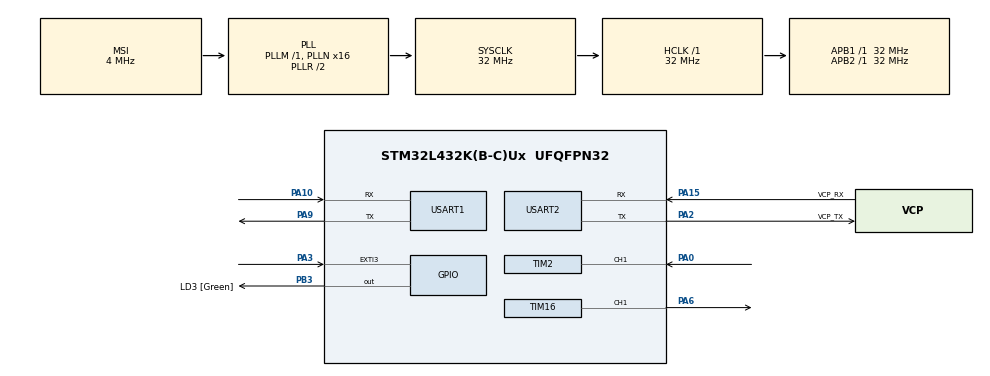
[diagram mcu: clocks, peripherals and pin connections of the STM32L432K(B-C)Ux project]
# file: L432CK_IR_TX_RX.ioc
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Dma.Request0=USART1_RX
Dma.Request1=USART1_TX
Dma.Request2=USART2_TX
Dma.USART1_RX.0.Direction=DMA_PERIPH_TO_MEMORY
Dma.USART1_RX.0.Instance=DMA1_Channel5
Dma.USART1_RX.0.MemDataAlignment=DMA_MDATAALIGN_BYTE
Dma.USART1_RX.0.MemInc=DMA_MINC_ENABLE
Dma.USART1_RX.0.Mode=DMA_CIRCULAR
Dma.USART1_RX.0.PeriphDataAlignment=DMA_PDATAALIGN_BYTE
Dma.USART1_RX.0.PeriphInc=DMA_PINC_DISABLE
Dma.USART1_RX.0.Priority=DMA_PRIORITY_MEDIUM
Dma.USART1_TX.1.Direction=DMA_MEMORY_TO_PERIPH
Dma.USART1_TX.1.Instance=DMA1_Channel4
Dma.USART1_TX.1.MemDataAlignment=DMA_MDATAALIGN_BYTE
Dma.USART1_TX.1.MemInc=DMA_MINC_ENABLE
Dma.USART1_TX.1.Mode=DMA_NORMAL
Dma.USART1_TX.1.PeriphDataAlignment=DMA_PDATAALIGN_BYTE
Dma.USART1_TX.1.PeriphInc=DMA_PINC_DISABLE
Dma.USART1_TX.1.Priority=DMA_PRIORITY_LOW
Dma.USART2_TX.2.Direction=DMA_MEMORY_TO_PERIPH
Dma.USART2_TX.2.Instance=DMA1_Channel7
Dma.USART2_TX.2.MemDataAlignment=DMA_MDATAALIGN_BYTE
Dma.USART2_TX.2.MemInc=DMA_MINC_ENABLE
Dma.USART2_TX.2.Mode=DMA_NORMAL
Dma.USART2_TX.2.PeriphDataAlignment=DMA_PDATAALIGN_BYTE
Dma.USART2_TX.2.PeriphInc=DMA_PINC_DISABLE
Dma.USART2_TX.2.Priority=DMA_PRIORITY_LOW
Mcu.Family=STM32L4
Mcu.Name=STM32L432K(B-C)Ux
Mcu.Package=UFQFPN32
NVIC.DMA1_Channel4_IRQn=true\:0\:0\:false\:false\:true\:false\:true\:true
NVIC.DMA1_Channel5_IRQn=true\:0\:0\:false\:false\:true\:false\:true\:true
NVIC.DMA1_Channel7_IRQn=true\:0\:0\:false\:false\:true\:false\:true\:true
NVIC.EXTI3_IRQn=true\:3\:0\:true\:false\:true\:true\:true\:true
NVIC.PriorityGroup=NVIC_PRIORITYGROUP_4
NVIC.TIM1_BRK_TIM15_IRQn=true\:2\:0\:true\:false\:true\:true\:true\:true
NVIC.TIM2_IRQn=true\:1\:0\:true\:false\:true\:true\:true\:true
NVIC.USART1_IRQn=true\:0\:0\:false\:false\:true\:true\:true\:true
NVIC.USART2_IRQn=true\:0\:0\:false\:false\:true\:true\:true\:true
PA0.Signal=S_TIM2_CH1
PA10.Mode=Asynchronous
PA10.Signal=USART1_RX
PA13\ (JTMS-SWDIO).GPIO_Label=SWDIO
PA13\ (JTMS-SWDIO).Mode=Serial_Wire
PA13\ (JTMS-SWDIO).Signal=SYS_JTMS-SWDIO
PA14\ (JTCK-SWCLK).GPIO_Label=SWCLK
PA14\ (JTCK-SWCLK).Mode=Serial_Wire
PA14\ (JTCK-SWCLK).Signal=SYS_JTCK-SWCLK
PA15\ (JTDI).GPIO_Label=VCP_RX
PA15\ (JTDI).Mode=Asynchronous
PA15\ (JTDI).Signal=USART2_RX
PA2.GPIO_Label=VCP_TX
PA2.Mode=Asynchronous
PA2.Signal=USART2_TX
PA3.Signal=GPXTI3
PA6.Signal=S_TIM16_CH1
PA9.Mode=Asynchronous
PA9.Signal=USART1_TX
PB3\ (JTDO-TRACESWO).GPIO_Label=LD3 [Green]
PB3\ (JTDO-TRACESWO).Signal=GPIO_Output
ProjectManager.HeapSize=0x200
ProjectManager.StackSize=0x400
ProjectManager.TargetToolchain=MDK-ARM V5.32
RCC.AHBFreq_Value=32000000
RCC.APB1Freq_Value=32000000
RCC.APB1TimFreq_Value=32000000
RCC.APB2Freq_Value=32000000
RCC.APB2TimFreq_Value=32000000
RCC.CortexFreq_Value=32000000
RCC.HCLKFreq_Value=32000000
RCC.HSE_VALUE=8000000
RCC.HSI16_VALUE=16000000
RCC.HSI48_VALUE=48000000
RCC.HSI_VALUE=16000000
RCC.LSE_VALUE=32768
RCC.MSI_VALUE=4000000
RCC.PLLMUL=RCC_PLLMUL_4
RCC.PLLN=16
RCC.SYSCLKFreq_VALUE=32000000
RCC.SYSCLKSource=RCC_SYSCLKSOURCE_PLLCLK
RCC.VCOOutputFreq_Value=64000000
SH.S_TIM16_CH1.0=TIM16_CH1,PWM Generation1 CH1
SH.S_TIM2_CH1.0=TIM2_CH1,PWM_Input_1
TIM15.AutoReloadPreload=TIM_AUTORELOAD_PRELOAD_ENABLE
TIM15.Period=888
TIM15.Prescaler=31
TIM15.TIM_MasterOutputTrigger=TIM_TRGO_RESET
TIM16.AutoReloadPreload=TIM_AUTORELOAD_PRELOAD_ENABLE
TIM16.Channel=TIM_CHANNEL_1
TIM16.Period=842
TIM16.Pulse=210
TIM2.ICPolarity_1=TIM_INPUTCHANNELPOLARITY_FALLING
TIM2.Period=3700
TIM2.Prescaler=31
TIM2.TIM_MasterOutputTrigger=TIM_TRGO_RESET
USART1.VirtualMode-Asynchronous=VM_ASYNC
USART2.VirtualMode-Asynchronous=VM_ASYNC
VP_TIM15_VS_ClockSourceINT.Mode=Internal
VP_TIM16_VS_ClockSourceINT.Mode=Enable_Timer
VP_TIM2_VS_ClockSourceINT.Mode=Internal
board=NUCLEO-L432KC

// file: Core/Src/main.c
/* USER CODE BEGIN Header */
/**
  ******************************************************************************
  * @file           : main.c
  * @brief          : Main program body
  ******************************************************************************
  * @attention
  *
  * Copyright (c) 2026 STMicroelectronics.
  * All rights reserved.
  *
  * This software is licensed under terms that can be found in the LICENSE file
  * in the root directory of this software component.
  * If no LICENSE file comes with this software, it is provided AS-IS.
  *
  ******************************************************************************
  */
/* USER CODE END Header */
#include "main.h"

/* USER CODE BEGIN Includes */
#include "app_ble_ir.h"
/* USER CODE END Includes */

TIM_HandleTypeDef htim2;
TIM_HandleTypeDef htim15;
TIM_HandleTypeDef htim16;

UART_HandleTypeDef huart1;
UART_HandleTypeDef huart2;
DMA_HandleTypeDef hdma_usart1_rx;
DMA_HandleTypeDef hdma_usart1_tx;
DMA_HandleTypeDef hdma_usart2_tx;

void SystemClock_Config(void);
static void MX_GPIO_Init(void);
static void MX_DMA_Init(void);
static void MX_USART2_UART_Init(void);
static void MX_TIM2_Init(void);
static void MX_TIM15_Init(void);
static void MX_TIM16_Init(void);
static void MX_USART1_UART_Init(void);

/* USER CODE BEGIN 0 */
void HAL_GPIO_EXTI_Callback(uint16_t GPIO_Pin)
{
  App_BleIr_OnExti(GPIO_Pin);
}
/* USER CODE END 0 */

int main(void)
{

  /* MCU Configuration--------------------------------------------------------*/

  /* Reset of all peripherals, Initializes the Flash interface and the Systick. */
  HAL_Init();

  /* Configure the system clock */
  SystemClock_Config();

  /* Initialize all configured peripherals */
  MX_GPIO_Init();
  MX_DMA_Init();
  MX_USART2_UART_Init();
  MX_TIM2_Init();
  MX_TIM15_Init();
  MX_TIM16_Init();
  MX_USART1_UART_Init();
  /* USER CODE BEGIN 2 */
  App_BleIr_Init();

  /* USER CODE END 2 */

  /* Infinite loop */
  while (1)
  {

    /* USER CODE BEGIN 3 */
    App_BleIr_Process();
  }
  /* USER CODE END 3 */
}

void SystemClock_Config(void)
{
  RCC_OscInitTypeDef RCC_OscInitStruct = {0};
  RCC_ClkInitTypeDef RCC_ClkInitStruct = {0};

  /** Configure the main internal regulator output voltage
  */
  if (HAL_PWREx_ControlVoltageScaling(PWR_REGULATOR_VOLTAGE_SCALE1) != HAL_OK)
  {
    Error_Handler();
  }

  /** Initializes the RCC Oscillators according to the specified parameters
  * in the RCC_OscInitTypeDef structure.
  */
  RCC_OscInitStruct.OscillatorType = RCC_OSCILLATORTYPE_MSI;
  RCC_OscInitStruct.MSIState = RCC_MSI_ON;
  RCC_OscInitStruct.MSICalibrationValue = 0;
  RCC_OscInitStruct.MSIClockRange = RCC_MSIRANGE_6;
  RCC_OscInitStruct.PLL.PLLState = RCC_PLL_ON;
  RCC_OscInitStruct.PLL.PLLSource = RCC_PLLSOURCE_MSI;
  RCC_OscInitStruct.PLL.PLLM = 1;
  RCC_OscInitStruct.PLL.PLLN = 16;
  RCC_OscInitStruct.PLL.PLLP = RCC_PLLP_DIV7;
  RCC_OscInitStruct.PLL.PLLQ = RCC_PLLQ_DIV2;
  RCC_OscInitStruct.PLL.PLLR = RCC_PLLR_DIV2;
  if (HAL_RCC_OscConfig(&RCC_OscInitStruct) != HAL_OK)
  {
    Error_Handler();
  }

  /** Initializes the CPU, AHB and APB buses clocks
  */
  RCC_ClkInitStruct.ClockType = RCC_CLOCKTYPE_HCLK|RCC_CLOCKTYPE_SYSCLK
                              |RCC_CLOCKTYPE_PCLK1|RCC_CLOCKTYPE_PCLK2;
  RCC_ClkInitStruct.SYSCLKSource = RCC_SYSCLKSOURCE_PLLCLK;
  RCC_ClkInitStruct.AHBCLKDivider = RCC_SYSCLK_DIV1;
  RCC_ClkInitStruct.APB1CLKDivider = RCC_HCLK_DIV1;
  RCC_ClkInitStruct.APB2CLKDivider = RCC_HCLK_DIV1;

  if (HAL_RCC_ClockConfig(&RCC_ClkInitStruct, FLASH_LATENCY_1) != HAL_OK)
  {
    Error_Handler();
  }
}

static void MX_TIM2_Init(void)
{

  TIM_ClockConfigTypeDef sClockSourceConfig = {0};
  TIM_SlaveConfigTypeDef sSlaveConfig = {0};
  TIM_IC_InitTypeDef sConfigIC = {0};
  TIM_MasterConfigTypeDef sMasterConfig = {0};

  htim2.Instance = TIM2;
  htim2.Init.Prescaler = 31;
  htim2.Init.CounterMode = TIM_COUNTERMODE_UP;
  htim2.Init.Period = 3700;
  htim2.Init.ClockDivision = TIM_CLOCKDIVISION_DIV1;
  htim2.Init.AutoReloadPreload = TIM_AUTORELOAD_PRELOAD_DISABLE;
  if (HAL_TIM_Base_Init(&htim2) != HAL_OK)
  {
    Error_Handler();
  }
  sClockSourceConfig.ClockSource = TIM_CLOCKSOURCE_INTERNAL;
  if (HAL_TIM_ConfigClockSource(&htim2, &sClockSourceConfig) != HAL_OK)
  {
    Error_Handler();
  }
  if (HAL_TIM_IC_Init(&htim2) != HAL_OK)
  {
    Error_Handler();
  }
  sSlaveConfig.SlaveMode = TIM_SLAVEMODE_RESET;
  sSlaveConfig.InputTrigger = TIM_TS_TI1FP1;
  sSlaveConfig.TriggerPolarity = TIM_INPUTCHANNELPOLARITY_FALLING;
  sSlaveConfig.TriggerPrescaler = TIM_ICPSC_DIV1;
  sSlaveConfig.TriggerFilter = 0;
  if (HAL_TIM_SlaveConfigSynchro(&htim2, &sSlaveConfig) != HAL_OK)
  {
    Error_Handler();
  }
  sConfigIC.ICPolarity = TIM_INPUTCHANNELPOLARITY_FALLING;
  sConfigIC.ICSelection = TIM_ICSELECTION_DIRECTTI;
  sConfigIC.ICPrescaler = TIM_ICPSC_DIV1;
  sConfigIC.ICFilter = 0;
  if (HAL_TIM_IC_ConfigChannel(&htim2, &sConfigIC, TIM_CHANNEL_1) != HAL_OK)
  {
    Error_Handler();
  }
  sConfigIC.ICPolarity = TIM_INPUTCHANNELPOLARITY_RISING;
  sConfigIC.ICSelection = TIM_ICSELECTION_INDIRECTTI;
  if (HAL_TIM_IC_ConfigChannel(&htim2, &sConfigIC, TIM_CHANNEL_2) != HAL_OK)
  {
    Error_Handler();
  }
  sMasterConfig.MasterOutputTrigger = TIM_TRGO_RESET;
  sMasterConfig.MasterSlaveMode = TIM_MASTERSLAVEMODE_DISABLE;
  if (HAL_TIMEx_MasterConfigSynchronization(&htim2, &sMasterConfig) != HAL_OK)
  {
    Error_Handler();
  }
  /* USER CODE BEGIN TIM2_Init 2 */

  /* Re-apply slave reset mode AFTER IC channel config, because
     HAL_TIM_IC_ConfigChannel on CH1 can clobber SMCR. */
  {
    TIM_SlaveConfigTypeDef sSlaveRe = {0};
    sSlaveRe.SlaveMode        = TIM_SLAVEMODE_RESET;
    sSlaveRe.InputTrigger     = TIM_TS_TI1FP1;
    sSlaveRe.TriggerPolarity  = TIM_TRIGGERPOLARITY_FALLING;
    sSlaveRe.TriggerPrescaler = TIM_ICPSC_DIV1;
    sSlaveRe.TriggerFilter    = 0;
    HAL_TIM_SlaveConfigSynchro(&htim2, &sSlaveRe);
  }

  /* USER CODE END TIM2_Init 2 */

}

static void MX_TIM15_Init(void)
{

  TIM_ClockConfigTypeDef sClockSourceConfig = {0};
  TIM_MasterConfigTypeDef sMasterConfig = {0};

  htim15.Instance = TIM15;
  htim15.Init.Prescaler = 31;
  htim15.Init.CounterMode = TIM_COUNTERMODE_UP;
  htim15.Init.Period = 888;
  htim15.Init.ClockDivision = TIM_CLOCKDIVISION_DIV1;
  htim15.Init.RepetitionCounter = 0;
  htim15.Init.AutoReloadPreload = TIM_AUTORELOAD_PRELOAD_ENABLE;
  if (HAL_TIM_Base_Init(&htim15) != HAL_OK)
  {
    Error_Handler();
  }
  sClockSourceConfig.ClockSource = TIM_CLOCKSOURCE_INTERNAL;
  if (HAL_TIM_ConfigClockSource(&htim15, &sClockSourceConfig) != HAL_OK)
  {
    Error_Handler();
  }
  sMasterConfig.MasterOutputTrigger = TIM_TRGO_RESET;
  sMasterConfig.MasterSlaveMode = TIM_MASTERSLAVEMODE_DISABLE;
  if (HAL_TIMEx_MasterConfigSynchronization(&htim15, &sMasterConfig) != HAL_OK)
  {
    Error_Handler();
  }

}

static void MX_TIM16_Init(void)
{

  TIM_OC_InitTypeDef sConfigOC = {0};
  TIM_BreakDeadTimeConfigTypeDef sBreakDeadTimeConfig = {0};

  htim16.Instance = TIM16;
  htim16.Init.Prescaler = 0;
  htim16.Init.CounterMode = TIM_COUNTERMODE_UP;
  htim16.Init.Period = 842;
  htim16.Init.ClockDivision = TIM_CLOCKDIVISION_DIV1;
  htim16.Init.RepetitionCounter = 0;
  htim16.Init.AutoReloadPreload = TIM_AUTORELOAD_PRELOAD_ENABLE;
  if (HAL_TIM_Base_Init(&htim16) != HAL_OK)
  {
    Error_Handler();
  }
  if (HAL_TIM_PWM_Init(&htim16) != HAL_OK)
  {
    Error_Handler();
  }
  sConfigOC.OCMode = TIM_OCMODE_PWM1;
  sConfigOC.Pulse = 210;
  sConfigOC.OCPolarity = TIM_OCPOLARITY_HIGH;
  sConfigOC.OCNPolarity = TIM_OCNPOLARITY_HIGH;
  sConfigOC.OCFastMode = TIM_OCFAST_DISABLE;
  sConfigOC.OCIdleState = TIM_OCIDLESTATE_RESET;
  sConfigOC.OCNIdleState = TIM_OCNIDLESTATE_RESET;
  if (HAL_TIM_PWM_ConfigChannel(&htim16, &sConfigOC, TIM_CHANNEL_1) != HAL_OK)
  {
    Error_Handler();
  }
  sBreakDeadTimeConfig.OffStateRunMode = TIM_OSSR_DISABLE;
  sBreakDeadTimeConfig.OffStateIDLEMode = TIM_OSSI_DISABLE;
  sBreakDeadTimeConfig.LockLevel = TIM_LOCKLEVEL_OFF;
  sBreakDeadTimeConfig.DeadTime = 0;
  sBreakDeadTimeConfig.BreakState = TIM_BREAK_DISABLE;
  sBreakDeadTimeConfig.BreakPolarity = TIM_BREAKPOLARITY_HIGH;
  sBreakDeadTimeConfig.AutomaticOutput = TIM_AUTOMATICOUTPUT_DISABLE;
  if (HAL_TIMEx_ConfigBreakDeadTime(&htim16, &sBreakDeadTimeConfig) != HAL_OK)
  {
    Error_Handler();
  }
  HAL_TIM_MspPostInit(&htim16);

}

static void MX_USART1_UART_Init(void)
{

  huart1.Instance = USART1;
  huart1.Init.BaudRate = 115200;
  huart1.Init.WordLength = UART_WORDLENGTH_8B;
  huart1.Init.StopBits = UART_STOPBITS_1;
  huart1.Init.Parity = UART_PARITY_NONE;
  huart1.Init.Mode = UART_MODE_TX_RX;
  huart1.Init.HwFlowCtl = UART_HWCONTROL_NONE;
  huart1.Init.OverSampling = UART_OVERSAMPLING_16;
  huart1.Init.OneBitSampling = UART_ONE_BIT_SAMPLE_DISABLE;
  huart1.AdvancedInit.AdvFeatureInit = UART_ADVFEATURE_NO_INIT;
  if (HAL_UART_Init(&huart1) != HAL_OK)
  {
    Error_Handler();
  }

}

static void MX_USART2_UART_Init(void)
{

  huart2.Instance = USART2;
  huart2.Init.BaudRate = 115200;
  huart2.Init.WordLength = UART_WORDLENGTH_8B;
  huart2.Init.StopBits = UART_STOPBITS_1;
  huart2.Init.Parity = UART_PARITY_NONE;
  huart2.Init.Mode = UART_MODE_TX_RX;
  huart2.Init.HwFlowCtl = UART_HWCONTROL_NONE;
  huart2.Init.OverSampling = UART_OVERSAMPLING_16;
  huart2.Init.OneBitSampling = UART_ONE_BIT_SAMPLE_DISABLE;
  huart2.AdvancedInit.AdvFeatureInit = UART_ADVFEATURE_NO_INIT;
  if (HAL_UART_Init(&huart2) != HAL_OK)
  {
    Error_Handler();
  }

}

static void MX_DMA_Init(void)
{

  /* DMA controller clock enable */
  __HAL_RCC_DMA1_CLK_ENABLE();

  /* DMA interrupt init */
  /* DMA1_Channel4_IRQn interrupt configuration */
  HAL_NVIC_SetPriority(DMA1_Channel4_IRQn, 0, 0);
  HAL_NVIC_EnableIRQ(DMA1_Channel4_IRQn);
  /* DMA1_Channel5_IRQn interrupt configuration */
  HAL_NVIC_SetPriority(DMA1_Channel5_IRQn, 0, 0);
  HAL_NVIC_EnableIRQ(DMA1_Channel5_IRQn);
  /* DMA1_Channel7_IRQn interrupt configuration */
  HAL_NVIC_SetPriority(DMA1_Channel7_IRQn, 0, 0);
  HAL_NVIC_EnableIRQ(DMA1_Channel7_IRQn);

}

static void MX_GPIO_Init(void)
{
  GPIO_InitTypeDef GPIO_InitStruct = {0};

  /* GPIO Ports Clock Enable */
  __HAL_RCC_GPIOA_CLK_ENABLE();
  __HAL_RCC_GPIOB_CLK_ENABLE();

  /*Configure GPIO pin Output Level */
  HAL_GPIO_WritePin(LD3_GPIO_Port, LD3_Pin, GPIO_PIN_RESET);

  /*Configure GPIO pin : PA3 */
  GPIO_InitStruct.Pin = GPIO_PIN_3;
  GPIO_InitStruct.Mode = GPIO_MODE_IT_RISING;
  GPIO_InitStruct.Pull = GPIO_NOPULL;
  HAL_GPIO_Init(GPIOA, &GPIO_InitStruct);

  /*Configure GPIO pin : LD3_Pin */
  GPIO_InitStruct.Pin = LD3_Pin;
  GPIO_InitStruct.Mode = GPIO_MODE_OUTPUT_PP;
  GPIO_InitStruct.Pull = GPIO_NOPULL;
  GPIO_InitStruct.Speed = GPIO_SPEED_FREQ_LOW;
  HAL_GPIO_Init(LD3_GPIO_Port, &GPIO_InitStruct);

  /* EXTI interrupt init*/
  HAL_NVIC_SetPriority(EXTI3_IRQn, 3, 0);
  HAL_NVIC_EnableIRQ(EXTI3_IRQn);

}

void Error_Handler(void)
{
  __disable_irq();
  while (1)
  {
  }
}
